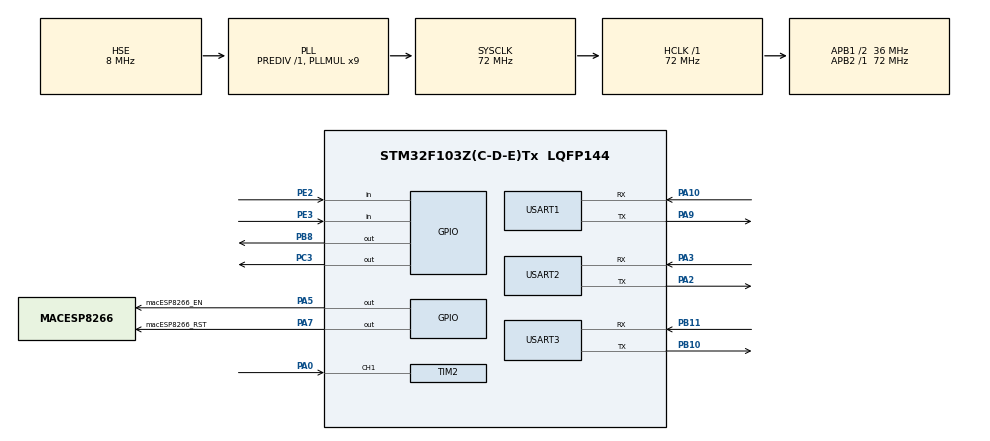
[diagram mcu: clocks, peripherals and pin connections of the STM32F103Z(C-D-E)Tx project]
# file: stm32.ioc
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Mcu.Family=STM32F1
Mcu.Name=STM32F103Z(C-D-E)Tx
Mcu.Package=LQFP144
NVIC.PriorityGroup=NVIC_PRIORITYGROUP_4
NVIC.TIM2_IRQn=true\:0\:0\:false\:false\:true\:false\:true\:true\:true
NVIC.USART1_IRQn=true\:0\:0\:false\:false\:true\:false\:true\:true\:true
NVIC.USART2_IRQn=true\:0\:0\:false\:false\:true\:false\:true\:true\:true
NVIC.USART3_IRQn=true\:0\:0\:false\:false\:true\:false\:true\:true\:true
OSC_IN.Mode=HSE-External-Oscillator
OSC_IN.Signal=RCC_OSC_IN
OSC_OUT.Mode=HSE-External-Oscillator
OSC_OUT.Signal=RCC_OSC_OUT
PA0-WKUP.Signal=S_TIM2_CH1_ETR
PA10.Mode=Asynchronous
PA10.Signal=USART1_RX
PA2.Mode=Asynchronous
PA2.Signal=USART2_TX
PA3.Mode=Asynchronous
PA3.Signal=USART2_RX
PA5.GPIO_Label=macESP8266_EN
PA5.Signal=GPIO_Output
PA7.GPIO_Label=macESP8266_RST
PA7.Signal=GPIO_Output
PA9.Mode=Asynchronous
PA9.Signal=USART1_TX
PB10.Mode=Asynchronous
PB10.Signal=USART3_TX
PB11.Mode=Asynchronous
PB11.Signal=USART3_RX
PB8.Signal=GPIO_Output
PC14-OSC32_IN.Mode=LSE-External-Oscillator
PC14-OSC32_IN.Signal=RCC_OSC32_IN
PC15-OSC32_OUT.Mode=LSE-External-Oscillator
PC15-OSC32_OUT.Signal=RCC_OSC32_OUT
PC3.Signal=GPIO_Output
PE2.GPIO_PuPd=GPIO_PULLUP
PE2.Signal=GPIO_Input
PE3.GPIO_Mode=GPIO_MODE_INPUT
PE3.GPIO_PuPd=GPIO_PULLUP
PE3.Signal=GPIO_Input
ProjectManager.HeapSize=0x200
ProjectManager.StackSize=0x400
ProjectManager.TargetToolchain=MDK-ARM V5.32
RCC.AHBFreq_Value=72000000
RCC.APB1CLKDivider=RCC_HCLK_DIV2
RCC.APB1Freq_Value=36000000
RCC.APB1TimFreq_Value=72000000
RCC.APB2Freq_Value=72000000
RCC.APB2TimFreq_Value=72000000
RCC.HCLKFreq_Value=72000000
RCC.PLLMUL=RCC_PLL_MUL9
RCC.PLLSourceVirtual=RCC_PLLSOURCE_HSE
RCC.SYSCLKFreq_VALUE=72000000
RCC.SYSCLKSource=RCC_SYSCLKSOURCE_PLLCLK
RCC.USBFreq_Value=72000000
RealThread.RT-Thread.3.1.5.RTOSJjdevice=true
RealThread.RT-Thread.3.1.5.RTOSJjkernel=true
RealThread.RT-Thread.3.1.5.RTOSJjshell=true
SH.S_TIM2_CH1_ETR.0=TIM2_CH1,Input_Capture1_from_TI1
TIM2.AutoReloadPreload=TIM_AUTORELOAD_PRELOAD_ENABLE
TIM2.Channel-Input_Capture1_from_TI1=TIM_CHANNEL_1
TIM2.Prescaler=71
TIM3.AutoReloadPreload=TIM_AUTORELOAD_PRELOAD_ENABLE
TIM3.Period=10000
TIM3.Prescaler=71
USART1.VirtualMode=VM_ASYNC
USART2.VirtualMode=VM_ASYNC
USART3.VirtualMode=VM_ASYNC
VP_RealThread.RT-Thread_VS_RTOSJjdevice_3.1.5_3.1.5.Mode=RTOSJjdevice
VP_RealThread.RT-Thread_VS_RTOSJjkernel_3.1.5_3.1.5.Mode=RTOSJjkernel
VP_RealThread.RT-Thread_VS_RTOSJjshell_3.1.5_3.1.5.Mode=RTOSJjshell
VP_SYS_VS_ND.Mode=No_Debug
VP_TIM2_VS_ClockSourceINT.Mode=Internal
VP_TIM3_VS_ClockSourceINT.Mode=Internal
board=custom

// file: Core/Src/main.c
/* USER CODE BEGIN Header */
/**
  ******************************************************************************
  * @file           : main.c
  * @brief          : Main program body
  ******************************************************************************
  * @attention
  *
  * Copyright (c) 2023 STMicroelectronics.
  * All rights reserved.
  *
  * This software is licensed under terms that can be found in the LICENSE file
  * in the root directory of this software component.
  * If no LICENSE file comes with this software, it is provided AS-IS.
  *
  ******************************************************************************
  */
/* USER CODE END Header */
#include "main.h"
#include "tim.h"
#include "usart.h"
#include "gpio.h"

/* USER CODE BEGIN Includes */

#include "rtthread.h"
#include "beep.h"

/* USER CODE END Includes */

void SystemClock_Config(void);

/* USER CODE BEGIN 0 */
extern void MX_RT_Thread_Init(void);
extern void MX_RT_Thread_Process(void);

/* USER CODE END 0 */

int main(void)
{

  /* MCU Configuration--------------------------------------------------------*/

  /* Reset of all peripherals, Initializes the Flash interface and the Systick. */
  HAL_Init();

  /* Configure the system clock */
  SystemClock_Config();

  /* Initialize all configured peripherals */
  MX_GPIO_Init();
  MX_USART1_UART_Init();
  MX_TIM2_Init();
  MX_USART2_UART_Init();
  MX_USART3_UART_Init();
  MX_TIM3_Init();
  /* USER CODE BEGIN 2 */
	MX_RT_Thread_Init();
	MX_RT_Thread_Process();
	BEEP_Init(); //初始化蜂鸣器
  /* USER CODE END 2 */

  /* Infinite loop */
  while (1)
  {

    /* USER CODE BEGIN 3 */
	  //HAL_GPIO_WritePin(GPIOB,GPIO_PIN_8,GPIO_PIN_SET);
	  //HAL_Delay(3000); //延时 300ms
	  //HAL_GPIO_WritePin(GPIOB,GPIO_PIN_8,GPIO_PIN_RESET);
	  //HAL_Delay(3000);

  }
  /* USER CODE END 3 */
}

void SystemClock_Config(void)
{
  RCC_OscInitTypeDef RCC_OscInitStruct = {0};
  RCC_ClkInitTypeDef RCC_ClkInitStruct = {0};

  /** Initializes the RCC Oscillators according to the specified parameters
  * in the RCC_OscInitTypeDef structure.
  */
  RCC_OscInitStruct.OscillatorType = RCC_OSCILLATORTYPE_HSE;
  RCC_OscInitStruct.HSEState = RCC_HSE_ON;
  RCC_OscInitStruct.HSEPredivValue = RCC_HSE_PREDIV_DIV1;
  RCC_OscInitStruct.HSIState = RCC_HSI_ON;
  RCC_OscInitStruct.PLL.PLLState = RCC_PLL_ON;
  RCC_OscInitStruct.PLL.PLLSource = RCC_PLLSOURCE_HSE;
  RCC_OscInitStruct.PLL.PLLMUL = RCC_PLL_MUL9;
  if (HAL_RCC_OscConfig(&RCC_OscInitStruct) != HAL_OK)
  {
    Error_Handler();
  }

  /** Initializes the CPU, AHB and APB buses clocks
  */
  RCC_ClkInitStruct.ClockType = RCC_CLOCKTYPE_HCLK|RCC_CLOCKTYPE_SYSCLK
                              |RCC_CLOCKTYPE_PCLK1|RCC_CLOCKTYPE_PCLK2;
  RCC_ClkInitStruct.SYSCLKSource = RCC_SYSCLKSOURCE_PLLCLK;
  RCC_ClkInitStruct.AHBCLKDivider = RCC_SYSCLK_DIV1;
  RCC_ClkInitStruct.APB1CLKDivider = RCC_HCLK_DIV2;
  RCC_ClkInitStruct.APB2CLKDivider = RCC_HCLK_DIV1;

  if (HAL_RCC_ClockConfig(&RCC_ClkInitStruct, FLASH_LATENCY_2) != HAL_OK)
  {
    Error_Handler();
  }
}

void Error_Handler(void)
{
  __disable_irq();
  while (1)
  {
  }
}
